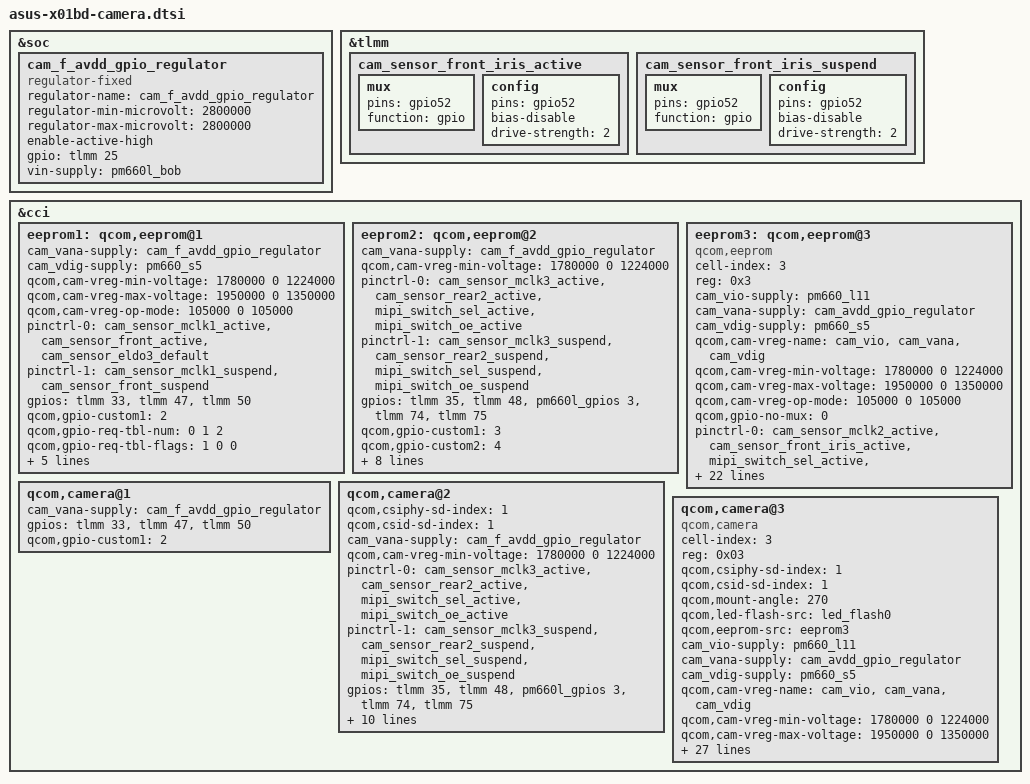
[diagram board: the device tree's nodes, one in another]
// SPDX-License-Identifier: GPL-2.0
// Copyright (C) 2021 Atom-X-Devs < https://www.github.com/Atom-X-Devs >

// asus X01BD changes
&soc {
	cam_f_avdd_gpio_regulator: cam_f_avdd_gpio_regulator {
		compatible = "regulator-fixed";
		regulator-name = "cam_f_avdd_gpio_regulator";
		regulator-min-microvolt = <2800000>;
		regulator-max-microvolt = <2800000>;
		enable-active-high;
		gpio = <&tlmm 25 0>;
		vin-supply = <&pm660l_bob>;
	};
};

&tlmm {
	cam_sensor_front_iris_active: cam_sensor_front_iris_active {
		/* RESET */
		mux {
			pins = "gpio52";
			function = "gpio";
		};

		config {
			pins = "gpio52";
			bias-disable; /* No PULL */
			drive-strength = <2>; /* 2 MA */
		};
	};

	cam_sensor_front_iris_suspend: cam_sensor_front_iris_suspend{
		/* RESET */
		mux {
			pins = "gpio52";
			function = "gpio";
		};

		config {
			pins = "gpio52";
			bias-disable; /* No PULL */
			drive-strength = <2>; /* 2 MA */
		};
	};
};

&cci {
	eeprom1: qcom,eeprom@1 {
		cam_vana-supply = <&cam_f_avdd_gpio_regulator>;
		cam_vdig-supply = <&pm660_s5>;
		qcom,cam-vreg-min-voltage = <1780000 0 1224000>;
		qcom,cam-vreg-max-voltage = <1950000 0 1350000>;
		qcom,cam-vreg-op-mode = <105000 0 105000>;
		pinctrl-0 = <&cam_sensor_mclk1_active
					&cam_sensor_front_active
					&cam_sensor_eldo3_default>;
		pinctrl-1 = <&cam_sensor_mclk1_suspend
				 &cam_sensor_front_suspend>;
		gpios = <&tlmm 33 0>,
				<&tlmm 47 0>,
				<&tlmm 50 0>;
		qcom,gpio-custom1 = <2>;
		qcom,gpio-req-tbl-num = <0 1 2>;
		qcom,gpio-req-tbl-flags = <1 0 0>;
		qcom,gpio-req-tbl-label = "CAMIF_MCLK1",
					  "CAM_RESET1",
					  "CAM_VDIG1";
		qcom,sensor-position = <1>;
		clocks = <&clock_mmss MCLK1_CLK_SRC>,
			<&clock_mmss MMSS_CAMSS_MCLK1_CLK>;
	};

	eeprom2: qcom,eeprom@2 {
		cam_vana-supply = <&cam_f_avdd_gpio_regulator>;
		qcom,cam-vreg-min-voltage = <1780000 0 1224000>;
		pinctrl-0 = <&cam_sensor_mclk3_active
				 &cam_sensor_rear2_active
			           &mipi_switch_sel_active
				      &mipi_switch_oe_active>;
		pinctrl-1 = <&cam_sensor_mclk3_suspend
				 &cam_sensor_rear2_suspend
				    &mipi_switch_sel_suspend
				       &mipi_switch_oe_suspend>;
		gpios = <&tlmm 35 0>,
			<&tlmm 48 0>,
			<&pm660l_gpios 3 0>,
			<&tlmm 74 0>,
			<&tlmm 75 0>;
		qcom,gpio-custom1 = <3>;
		qcom,gpio-custom2 = <4>;
		qcom,gpio-req-tbl-num = <0 1 2 3 4>;
		qcom,gpio-req-tbl-flags = <1 0 0 0 0>;
		qcom,gpio-req-tbl-label = "CAMIF_MCLK3",
					"CAM_RESET2",
					"CAM_VDIG2",
					"mipi_switch_sel",
					"mipi_switch_oe";
		qcom,sensor-position = <0>;
		clocks = <&clock_mmss MCLK3_CLK_SRC>,
			<&clock_mmss MMSS_CAMSS_MCLK3_CLK>;
	};

	eeprom3: qcom,eeprom@3 {
		cell-index = <3>;
		reg = <0x3>;
		compatible = "qcom,eeprom";
		cam_vio-supply = <&pm660_l11>;
		cam_vana-supply = <&cam_avdd_gpio_regulator>;
		cam_vdig-supply = <&pm660_s5>;
		qcom,cam-vreg-name = "cam_vio", "cam_vana", "cam_vdig";
		qcom,cam-vreg-min-voltage = <1780000 0 1224000>;
		qcom,cam-vreg-max-voltage = <1950000 0 1350000>;
		qcom,cam-vreg-op-mode = <105000 0 105000>;
		qcom,gpio-no-mux = <0>;
		pinctrl-names = "cam_default", "cam_suspend";
		pinctrl-0 = <&cam_sensor_mclk2_active
				 &cam_sensor_front_iris_active
				   &mipi_switch_sel_active
					&mipi_switch_oe_active>;
		pinctrl-1 = <&cam_sensor_mclk2_suspend
				 &cam_sensor_front_iris_suspend
				  &mipi_switch_sel_suspend
				    &mipi_switch_oe_suspend>;
		gpios = <&tlmm 34 0>,
			<&tlmm 52 0>,
			<&pm660l_gpios 3 0>,
			<&tlmm 74 0>,
			<&tlmm 75 0>;
		qcom,gpio-reset = <1>;
		qcom,gpio-vdig = <2>;
		qcom,gpio-custom1 = <3>;
		qcom,gpio-custom2 = <4>;
		qcom,gpio-req-tbl-num = <0 1 2 3 4>;
		qcom,gpio-req-tbl-flags = <1 0 0 0 0>;
		qcom,gpio-req-tbl-label = "CAMIF_MCLK2",
					"CAM_RESET2",
					"CAM_VDIG3",
					"mipi_switch_sel",
					"mipi_switch_oe";
		qcom,sensor-position = <0>;
		qcom,sensor-mode = <0>;
		qcom,cci-master = <0>;
		status = "ok";
		clocks = <&clock_mmss MCLK2_CLK_SRC>,
			<&clock_mmss MMSS_CAMSS_MCLK2_CLK>;
		clock-names = "cam_src_clk", "cam_clk";
		qcom,clock-rates = <24000000 0>;
	};

	qcom,camera@1 {
		cam_vana-supply = <&cam_f_avdd_gpio_regulator>;
		gpios = <&tlmm 33 0>,
				<&tlmm 47 0>,
				<&tlmm 50 0>;
		/delete-property/ qcom,gpio-vdig;
		qcom,gpio-custom1 = <2>;
	};

	qcom,camera@2 {
		qcom,csiphy-sd-index = <1>;
		qcom,csid-sd-index = <1>;
		cam_vana-supply = <&cam_f_avdd_gpio_regulator>;
		qcom,cam-vreg-min-voltage = <1780000 0 1224000>;
		pinctrl-0 = <&cam_sensor_mclk3_active
				 &cam_sensor_rear2_active
			           &mipi_switch_sel_active
				      &mipi_switch_oe_active>;
		pinctrl-1 = <&cam_sensor_mclk3_suspend
				 &cam_sensor_rear2_suspend
				    &mipi_switch_sel_suspend
				       &mipi_switch_oe_suspend>;
		gpios = <&tlmm 35 0>,
			<&tlmm 48 0>,
			<&pm660l_gpios 3 0>,
			<&tlmm 74 0>,
			<&tlmm 75 0>;
		qcom,gpio-custom1 = <3>;
		qcom,gpio-custom2 = <4>;
		qcom,gpio-req-tbl-num = <0 1 2 3 4>;
		qcom,gpio-req-tbl-flags = <1 0 0 0 0>;
		qcom,gpio-req-tbl-label = "CAMIF_MCLK3",
					"CAM_RESET2",
					"CAM_VDIG2",
					"mipi_switch_sel",
					"mipi_switch_oe";
		qcom,sensor-position = <0>;
		clocks = <&clock_mmss MCLK3_CLK_SRC>,
			<&clock_mmss MMSS_CAMSS_MCLK3_CLK>;
	};

	qcom,camera@3 {
		cell-index = <3>;
		compatible = "qcom,camera";
		reg = <0x03>;
		qcom,csiphy-sd-index = <1>;
		qcom,csid-sd-index = <1>;
		qcom,mount-angle = <270>;
		qcom,led-flash-src = <&led_flash0>;
		qcom,eeprom-src = <&eeprom3>;
		cam_vio-supply = <&pm660_l11>;
		cam_vana-supply = <&cam_avdd_gpio_regulator>;
		cam_vdig-supply = <&pm660_s5>;
		qcom,cam-vreg-name = "cam_vio", "cam_vana", "cam_vdig";
		qcom,cam-vreg-min-voltage = <1780000 0 1224000>;
		qcom,cam-vreg-max-voltage = <1950000 0 1350000>;
		qcom,cam-vreg-op-mode = <105000 0 105000>;
		qcom,gpio-no-mux = <0>;
		pinctrl-names = "cam_default", "cam_suspend";
		pinctrl-0 = <&cam_sensor_mclk2_active
				 &cam_sensor_front_iris_active
				   &mipi_switch_sel_active
					&mipi_switch_oe_active>;
		pinctrl-1 = <&cam_sensor_mclk2_suspend
				 &cam_sensor_front_iris_suspend
				  &mipi_switch_sel_suspend
				    &mipi_switch_oe_suspend>;
		gpios = <&tlmm 34 0>,
			<&tlmm 52 0>,
			<&pm660l_gpios 3 0>,
			<&tlmm 74 0>,
			<&tlmm 75 0>;
		qcom,gpio-reset = <1>;
		qcom,gpio-vdig = <2>;
		qcom,gpio-custom1 = <3>;
		qcom,gpio-custom2 = <4>;
		qcom,gpio-req-tbl-num = <0 1 2 3 4>;
		qcom,gpio-req-tbl-flags = <1 0 0 0 0>;
		qcom,gpio-req-tbl-label = "CAMIF_MCLK2",
					"CAM_RESET2",
					"CAM_VDIG3",
					"mipi_switch_sel",
					"mipi_switch_oe";
		qcom,sensor-position = <0>;
		qcom,sensor-mode = <0>;
		qcom,cci-master = <0>;
		status = "ok";
		clocks = <&clock_mmss MCLK2_CLK_SRC>,
			<&clock_mmss MMSS_CAMSS_MCLK2_CLK>;
		clock-names = "cam_src_clk", "cam_clk";
		qcom,clock-rates = <24000000 0>;
	};
};
